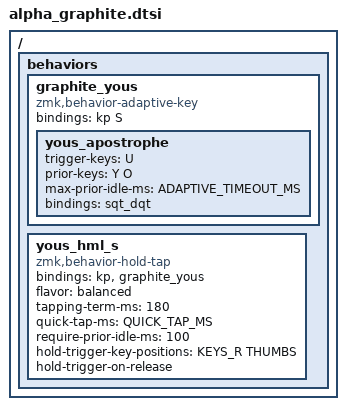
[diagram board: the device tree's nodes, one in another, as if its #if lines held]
/* >>> generated adaptive swaps (do not edit — run ./scripts/generate) >>> */
#include "../generated/alpha_graphite.dtsi"
/* <<< end generated adaptive swaps <<< */

#ifndef GRAPHITE_B
#define GRAPHITE_B &kp B
#endif
#ifndef GRAPHITE_C
#define GRAPHITE_C &kp C
#endif
#ifndef GRAPHITE_D
#define GRAPHITE_D &kp D
#endif
#ifndef GRAPHITE_E
#define GRAPHITE_E &hmr RALT E
#endif
#ifndef GRAPHITE_H
#define GRAPHITE_H &hmr RSHFT H
#endif
#ifndef GRAPHITE_L
#define GRAPHITE_L &kp L
#endif
#ifndef GRAPHITE_R
#define GRAPHITE_R &hml LALT R
#endif
#ifndef GRAPHITE_N
#define GRAPHITE_N &hml LGUI N
#endif
#ifndef GRAPHITE_S
#define GRAPHITE_S &hml LSHFT S
#endif
#ifndef GRAPHITE_W
#define GRAPHITE_W &kp W
#endif
#ifndef GRAPHITE_X
#define GRAPHITE_X &kp X
#endif
#ifndef GRAPHITE_Y
#define GRAPHITE_Y &kp Y
#endif
#ifndef GRAPHITE_O
#define GRAPHITE_O &kp O
#endif
#ifndef GRAPHITE_Q
#define GRAPHITE_Q &kp Q
#endif
#ifndef GRAPHITE_Z
#define GRAPHITE_Z &kp Z
#endif

ZMK_ADAPTIVE_KEY(graphite_yous, bindings = <&kp S>;
    yous_apostrophe { trigger-keys = <U>; prior-keys = <Y O>; max-prior-idle-ms = <ADAPTIVE_TIMEOUT_MS>; bindings = <&sqt_dqt>; };
)
ZMK_HOLD_TAP(yous_hml_s, bindings = <&kp>, <&graphite_yous>;
             flavor = "balanced"; tapping-term-ms = <180>;
             quick-tap-ms = <QUICK_TAP_MS>; require-prior-idle-ms = <100>;
             hold-trigger-key-positions = <KEYS_R THUMBS>;
             hold-trigger-on-release;)
#undef GRAPHITE_S
#define GRAPHITE_S &yous_hml_s LSHFT 0

#ifdef LUNA
ZMK_LAYER(Graphite,
    GRAPHITE_B GRAPHITE_L GRAPHITE_D GRAPHITE_W &kp G
    GRAPHITE_Y &kp F GRAPHITE_O &kp U &kp J
    GRAPHITE_N GRAPHITE_R &hml LCTRL T GRAPHITE_S &kp V
    &kp K GRAPHITE_H &hmr RCTRL A GRAPHITE_E &hmr RGUI I
    GRAPHITE_X &kp M GRAPHITE_C
    &kp P &dot_qmark &comma_excl
    ALPHA_THUMBS_L
    ALPHA_THUMBS_R
)
#else
ZMK_BASE_LAYER(Graphite,
//╭──────────┬──────────┬──────────┬──────────┬──────────╮   ╭──────────┬──────────┬──────────┬──────────┬──────────╮
    GRAPHITE_B GRAPHITE_L GRAPHITE_D GRAPHITE_W GRAPHITE_Z ,  &sqt_dqt   &kp F      GRAPHITE_O &kp U      &kp J      ,
//├──────────┼──────────┼──────────┼──────────┼──────────┤   ├──────────┼──────────┼──────────┼──────────┼──────────┤
   GRAPHITE_N GRAPHITE_R &hml LCTRL T GRAPHITE_S &kp G ,  GRAPHITE_Y GRAPHITE_H &hmr RCTRL A GRAPHITE_E &hmr RGUI I ,
//├──────────┼──────────┼──────────┼──────────┼──────────┤   ├──────────┼──────────┼──────────┼──────────┼──────────┤
    GRAPHITE_Q GRAPHITE_X &kp M      GRAPHITE_C &kp V      ,  &kp K      &kp P      &dot_qmark &minus_slash &comma_excl ,
//╰──────────┴──────────┴──────────┼──────────┼──────────┤   ├──────────┼──────────┼──────────┴──────────┴──────────╯
                    LH_NONE ALPHA_THUMBS_L , ALPHA_THUMBS_R RH_NONE
//                                 ╰──────────┴──────────╯   ╰──────────┴──────────╯
)
#endif
